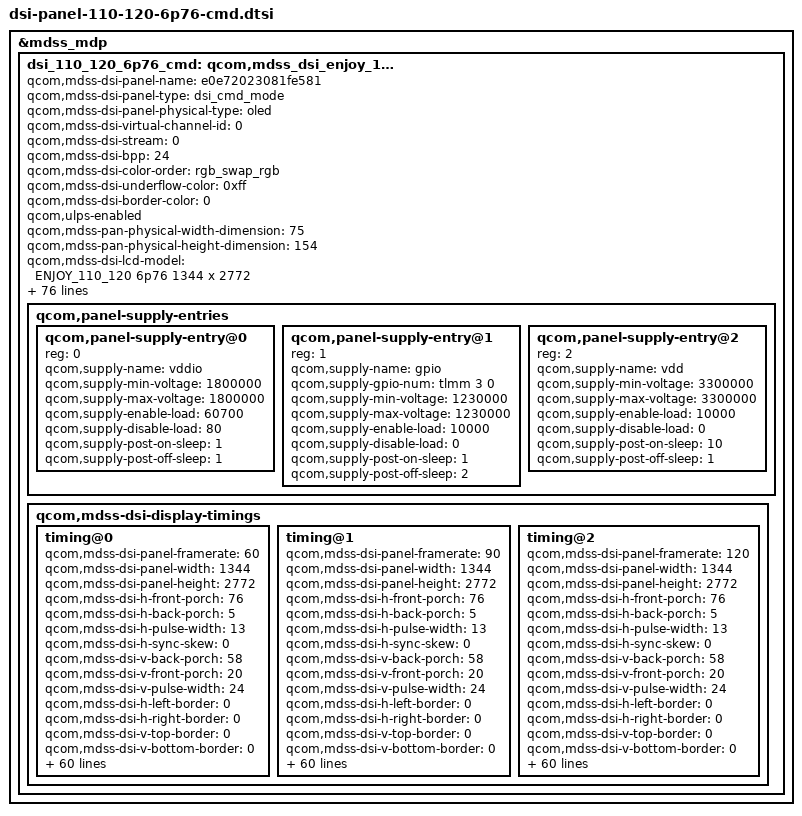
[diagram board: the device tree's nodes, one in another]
&mdss_mdp {
	dsi_110_120_6p76_cmd: qcom,mdss_dsi_enjoy_110_120_6p76_cmd {
		qcom,mdss-dsi-panel-name = "e0e72023081fe581";
		qcom,mdss-dsi-panel-type = "dsi_cmd_mode";
		qcom,mdss-dsi-panel-physical-type = "oled";
		qcom,mdss-dsi-virtual-channel-id = <0>;
		qcom,mdss-dsi-stream = <0>;
		qcom,mdss-dsi-bpp = <24>;
		qcom,mdss-dsi-color-order = "rgb_swap_rgb";
		qcom,mdss-dsi-underflow-color = <0xff>;
		qcom,mdss-dsi-border-color = <0>;
		qcom,ulps-enabled;
		qcom,mdss-pan-physical-width-dimension = <75>;
		qcom,mdss-pan-physical-height-dimension = <154>;
		qcom,mdss-dsi-lcd-model = "ENJOY_110_120 6p76 1344 x 2772";

		/* mipi dsi setting */
		qcom,dsi-ctrl-num = <0>;
		qcom,dsi-phy-num = <0>;
		qcom,dsi-sec-ctrl-num = <1>;
		qcom,dsi-sec-phy-num = <1>;
		qcom,mdss-dsi-traffic-mode = "non_burst_sync_event";
		qcom,mdss-dsi-lane-map = "lane_map_0123";
		qcom,mdss-dsi-bllp-eof-power-mode;
		qcom,mdss-dsi-bllp-power-mode;
		qcom,mdss-dsi-lane-0-state;
		qcom,mdss-dsi-lane-1-state;
		qcom,mdss-dsi-lane-2-state;
		qcom,mdss-dsi-lane-3-state;
		qcom,mdss-dsi-dma-trigger = "trigger_sw";
		qcom,mdss-dsi-mdp-trigger = "none";
		qcom,dsi-select-clocks = "mux_byte_clk0", "mux_pixel_clk0";
		qcom,dsi-select-sec-clocks = "mux_byte_clk1", "mux_pixel_clk1";

		/* TE setting */
		qcom,mdss-dsi-te-pin-select = <1>;
		qcom,mdss-dsi-wr-mem-start = <0x2c>;
		qcom,mdss-dsi-wr-mem-continue = <0x3c>;
		qcom,mdss-dsi-te-dcs-command = <1>;
		qcom,mdss-dsi-te-check-enable;
		qcom,mdss-dsi-te-using-te-pin;

		/* hdr setting */
		qcom,mdss-dsi-panel-hdr-enabled;
		qcom,mdss-dsi-panel-hdr-color-primaries = <14500 15500 32000
			17000 15500 30000 8000 3000>;
		qcom,mdss-dsi-panel-peak-brightness = <4200000>;
		qcom,mdss-dsi-panel-blackness-level = <3230>;

		/* hbm enable */
		qcom,mdss-dsi-panel-hbm-enabled;
		/* hbm delay threshold */
		qcom,mdss-dsi-hbm-left-delaythr = <0>;
		qcom,mdss-dsi-hbm-right-delaythr = <5000>;
		qcom,mdss-dsi-panel-read-batch-info-enabled;
		qcom,mdss-dsi-panel-batch-match-hbm-enabled;
		qcom,mdss-dsi-panel-batch-value = <0x04>;

		/* gpio setting */
		qcom,dsi-panel-gpio-address = <0x0F100000 0x1000>;
		qcom,dsi-panel-gpio-pins = <24 3>;
		qcom,dsi-panel-gpio-names = "reset-gpio", "vdd-gpio";

		/* esd check setting */
		qcom,mdss-dsi-panel-status-check-mode = "reg_read";
		qcom,mdss-dsi-panel-status-command = [
			06 01 00 01 00 00 01 0a
			06 01 00 01 00 00 01 03
			06 01 00 01 00 00 01 0d
			06 01 00 01 00 00 01 91
		];
		qcom,mdss-dsi-panel-status-command-state = "dsi_lp_mode";
		qcom,mdss-dsi-panel-status-value = <0x9c 0x01 0x00 0xab>;
		qcom,mdss-dsi-panel-status-read-length = <1 1 1 1>;
		qcom,esd-check-enabled;

		/* pcd detect*/
		qcom,mdss-dsi-panel-lcd-check-pcd-support;
		qcom,mdss-dsi-panel-lcd-pcd_value_compare_mode = <1>;
		qcom,mdss-dsi-panel-lcd-pcd_mask = <0xff>;
		qcom,mdss-dsi-panel-lcd-pcd_det_num = <1>;
		qcom,mdss-dsi-panel-lcd-check-pcd-expect_vals = <0xff>;

		/* check reg */
		qcom,mdss-dsi-panel-lcd-check-reg-enabled;
		qcom,mdss-dsi-panel-lcd-check-reg-expect_vals = <0x9c>;

		/* oem info */
		qcom,mdss-dsi-panel-oem-info-enabled;
		qcom,mdss-dsi-panel-oem-2d-barcode-enabled;
		qcom,mdss-dsi-panel-oem-sn-enabled;

		/* backlight setting */
		qcom,mdss-dsi-bl-pmic-control-type = "bl_ctrl_dcs";
		qcom,mdss-dsi-bl-min-level = <1>;
		qcom,mdss-dsi-bl-max-level = <4095>;
		qcom,mdss-brightness-max-level = <4095>;
		qcom,mdss-dsi-bl-inverted-dbv;
		qcom,mdss-dsi-bl-max-nit = <1000>;

		/* dfps setting */
		qcom,dsi-fps-list = <60 90 120>;

		/* power on/off timing setting */
		qcom,platform-reset-gpio = <&tlmm 24 0>;
		qcom,mdss-dsi-reset-sequence = <1 1>, <0 1>, <1 10>;
		qcom,mdss-dsi-reset-pre-off-sleep = <2>;
		qcom,mdss-dsi-panel-reset-in-lp11;
		qcom,panel-supply-entries {
			qcom,panel-supply-entry@0 {
					reg = <0>;
					qcom,supply-name = "vddio";
					qcom,supply-min-voltage = <1800000>;
					qcom,supply-max-voltage = <1800000>;
					qcom,supply-enable-load = <60700>;
					qcom,supply-disable-load = <80>;
					qcom,supply-post-on-sleep = <1>;
					qcom,supply-post-off-sleep = <1>;
			};
			qcom,panel-supply-entry@1 {
					reg = <1>;
					qcom,supply-name = "gpio";
					qcom,supply-gpio-num = <&tlmm 3 0>;
					qcom,supply-min-voltage = <1230000>;
					qcom,supply-max-voltage = <1230000>;
					qcom,supply-enable-load = <10000>;
					qcom,supply-disable-load = <0>;
					qcom,supply-post-on-sleep = <1>;
					qcom,supply-post-off-sleep = <2>;
			};
			qcom,panel-supply-entry@2 {
					reg = <2>;
					qcom,supply-name = "vdd";
					qcom,supply-min-voltage = <3300000>;
					qcom,supply-max-voltage = <3300000>;
					qcom,supply-enable-load = <10000>;
					qcom,supply-disable-load = <0>;
					qcom,supply-post-on-sleep = <10>;
					qcom,supply-post-off-sleep = <1>;
			};
		};
		/* display timing0 */
		qcom,mdss-dsi-display-timings {
			timing@0 {
				qcom,mdss-dsi-panel-framerate = <60>;
				qcom,mdss-dsi-panel-width = <1344>;
				qcom,mdss-dsi-panel-height = <2772>;
				qcom,mdss-dsi-h-front-porch = <76>;
				qcom,mdss-dsi-h-back-porch = <5>;
				qcom,mdss-dsi-h-pulse-width = <13>;
				qcom,mdss-dsi-h-sync-skew = <0>;
				qcom,mdss-dsi-v-back-porch = <58>;
				qcom,mdss-dsi-v-front-porch = <20>;
				qcom,mdss-dsi-v-pulse-width = <24>;
				qcom,mdss-dsi-h-left-border = <0>;
				qcom,mdss-dsi-h-right-border = <0>;
				qcom,mdss-dsi-v-top-border = <0>;
				qcom,mdss-dsi-v-bottom-border = <0>;
				qcom,mdss-dsi-panel-jitter = <0x4 0x1>;

				qcom,mdss-dsi-on-command = [
					39 01 00 00 00 00 06 F0 55 AA 52 08 05
					39 01 00 00 00 00 05 B7 85 00 00 81
					39 01 00 00 00 00 05 B8 05 00 00 81
					39 01 00 00 00 00 06 F0 55 AA 52 08 01
					15 01 00 00 00 00 02 6F 17
					15 01 00 00 00 00 02 D8 14
					39 01 00 00 00 00 06 F0 55 AA 52 08 07
					39 01 00 00 00 00 0E C0 1D 12 31 23 00 00 00 04 00 11 B3 00 00
					15 01 00 00 00 00 02 6F 00
					39 01 00 00 00 00 16 C9 21 00 2D 90 2D 90 00 00 3F D9 8E 80 3F D9 8E 80 80 08 1B F1 00
					15 01 00 00 00 00 02 6F 15
					39 01 00 00 00 00 10 C9 42 00 6E 42 6C DA 33 F0 2D 90 0F 94 94 00 00
					15 01 00 00 00 00 02 6F 24
					39 01 00 00 00 00 08 C9 00 00 00 00 00 00 00
					15 01 00 00 00 00 02 6F 00
					39 01 00 00 00 00 16 CA 27 00 2D 90 27 D9 00 00 00 00 00 00 3F DE 60 E8 80 00 00 00 00
					15 01 00 00 00 00 02 6F 15
					39 01 00 00 00 00 10 CA 42 6D 6E 42 D2 DA 33 D0 00 00 03 6C 9B 00 00
					15 01 00 00 00 00 02 6F 24
					39 01 00 00 00 00 08 CA 00 00 00 00 00 00 00
					15 01 00 00 00 00 02 6F 00
					39 01 00 00 00 00 16 CB 2D 00 2D 90 28 A4 00 00 3F DB B1 40 80 00 00 00 00 00 00 00 00
					15 01 00 00 00 00 02 6F 15
					39 01 00 00 00 00 10 CB 42 00 DB 52 66 47 33 E0 00 00 0C 94 66 00 00
					15 01 00 00 00 00 02 6F 24
					39 01 00 00 00 00 08 CB 00 00 00 00 00 00 00
					15 01 00 00 00 00 02 6F 00
					39 01 00 00 00 00 16 CC 2B 00 2D 90 2C B9 00 00 00 00 00 00 80 00 00 00 7F F8 0A 52 F0
					15 01 00 00 00 00 02 6F 15
					39 01 00 00 00 00 10 CC 42 67 DB 52 D2 47 33 CF D2 DC 00 6C 6B 00 00
					15 01 00 00 00 00 02 6F 24
					39 01 00 00 00 00 08 CC 00 00 00 00 00 00 00
                    			39 01 00 00 00 00 06 F0 55 AA 52 08 02
                   			39 01 00 00 00 00 05 88 02 9F 07 17
					39 01 00 00 00 00 06 F0 55 AA 52 08 01
					39 01 00 00 00 00 04 D2 00 40 00
					39 01 00 00 00 00 06 F0 55 AA 52 08 07
					15 01 00 00 00 00 02 C1 00
					15 01 00 00 00 00 02 C2 06
					15 01 00 00 00 00 02 C3 0C
					15 01 00 00 00 00 02 C4 0A
					15 01 00 00 00 00 02 C5 01
					15 01 00 00 00 00 02 C6 0D
					15 01 00 00 00 00 02 C7 07
					15 01 00 00 00 00 02 C8 0B
					39 01 00 00 00 00 06 F0 55 AA 52 08 00
					15 01 00 00 00 00 02 6F 02
					15 01 00 00 00 00 02 B5 46
					39 01 00 00 00 00 06 F0 55 AA 52 00 00
					39 01 00 00 00 00 05 FF AA 55 A5 00
					05 01 00 00 00 00 01 35
					39 01 00 00 00 00 05 3B 00 10 00 10
					39 01 00 00 00 00 02 53 20
					39 01 00 00 00 00 05 2A 00 00 05 3F
					39 01 00 00 00 00 05 2B 00 00 0A D3
					39 01 00 00 00 00 02 82 A6
					39 01 00 00 00 00 13 91 89 28 00 2C C2 00 02 50 04 BA 00 09 02 3C 01 DC 10 F0
					39 01 00 00 00 00 02 90 01
					39 01 00 00 00 00 02 03 01
					39 01 00 00 00 00 01 2C
					39 01 00 00 00 00 02 2F 01
					05 01 00 00 78 00 01 11
					05 01 00 00 00 00 01 29
				];

				qcom,mdss-dsi-off-command = [
					05 01 00 00 00 00 01 28
					05 01 00 00 64 00 01 10
				];

				qcom,mdss-dsi-fp-hbm-enable-commands = [
					39 01 00 00 00 00 03 51 0F FF
				];

				qcom,mdss-dsi-batchinfo-read-commands = [
					39 01 00 00 00 00 06 F0 55 AA 52 08 01
					06 01 00 01 00 00 01 DB
				];

				qcom,mdss-dsi-lhbm-enable-commands = [
					15 01 00 00 00 00 02 2F 04
					05 01 00 00 00 00 01 85
				];

				qcom,mdss-dsi-lhbm-disable-commands = [
					15 01 00 00 00 00 02 2F 01
					05 01 00 00 00 00 01 86
				];

				qcom,mdss-dsi-timing-switch-command = [
					15 01 00 00 0C 00 02 2F 01
				];

				qcom,mdss-dsi-lp1-command = [
					39 01 00 00 00 00 06 F0 55 AA 52 08 00
					15 00 00 00 00 00 02 6F 02
					15 00 00 00 00 00 02 B5 16
					15 00 00 00 00 00 02 2F 01
					05 00 00 00 00 00 01 39
					05 01 00 00 00 00 01 2C
				];

				qcom,mdss-dsi-nolp-command = [
					39 01 00 00 00 00 06 F0 55 AA 52 08 00
					15 00 00 00 00 00 02 6F 02
					15 00 00 00 00 00 02 B5 46
					05 00 00 00 00 00 01 38
					05 01 00 00 00 00 01 2C
				];

				qcom,mdss-dsi-alpm-low-light-commands = [
					39 01 00 00 00 00 05 51 01 77 00 03
				];

				qcom,mdss-dsi-alpm-middle-light-commands = [
					39 01 00 00 00 00 05 51 04 08 0A F0
				];

				qcom,mdss-dsi-alpm-high-light-commands = [
					39 01 00 00 00 00 05 51 05 73 0F FE
				];

				qcom,mdss-dsi-panel-lcd-check-reg-commands = [
					06 01 00 01 00 00 01 0a
				];

				qcom,mdss-dsi-oeminfo-read-commands = [
					39 01 00 00 00 00 06 F0 55 AA 52 08 01
					06 01 00 01 00 00 08 D6 00 00 00 00 00 00 00
					06 01 00 01 00 00 06 BF 00 00 00 00 00
					06 01 00 01 00 00 08 D7 00 00 00 00 00 00 00
				];

				qcom,mdss-dsi-lcd-pcd-check-open-commands = [
					39 01 00 00 0a 00 06 F0 55 AA 52 08 01
					39 01 00 00 0a 00 05 D0 00 31 00 00
				];

				qcom,mdss-dsi-lcd-pcd-check-reg-commands = [
					39 01 00 00 0a 00 06 F0 55 AA 52 08 01
					15 01 00 00 0a 00 02 6F 02
					06 01 00 00 0A 00 01 D0
				];

				qcom,mdss-dsi-lcd-pcd-check-close-commands = [
					39 01 00 00 78 00 06 F0 55 AA 52 08 01
					39 01 00 00 0A 00 03 D0 00 00
				];

				qcom,mdss-dsi-on-command-state = "dsi_lp_mode";
				qcom,mdss-dsi-off-command-state = "dsi_hs_mode";
				qcom,mdss-dsi-panel-lcd-check-reg-commands-state =
					"dsi_lp_mode";
				qcom,mdss-dsi-oeminfo-read-commands-state =
					"dsi_lp_mode";
				qcom,mdss-dsi-lcd-pcd-check-open-commands-state =
					"dsi_lp_mode";
				qcom,mdss-dsi-lcd-pcd-check-reg-commands-state =
					"dsi_lp_mode";
				qcom,mdss-dsi-lcd-pcd-check-close-commands-state =
					"dsi_lp_mode";

				qcom,mdss-dsi-h-sync-pulse = <0>;
				qcom,compression-mode = "dsc";
				qcom,mdss-dsc-version = <0x12>;
				qcom,mdss-dsc-slice-height = <44>;
				qcom,mdss-dsc-slice-width = <672>;
				qcom,mdss-dsc-slice-per-pkt = <2>;
				qcom,mdss-dsc-bit-per-component = <10>;
				qcom,mdss-dsc-bit-per-pixel = <8>;
				qcom,mdss-dsc-block-prediction-enable;
				qcom,mdss-dsi-panel-phy-timings = [00 14 05 05 13 1f 05
						05 05 06 02 04 12 0a];
				qcom,display-topology = <2 2 1>;
				qcom,default-topology-index = <0>;
			};
			timing@1 {
				qcom,mdss-dsi-panel-framerate = <90>;
				qcom,mdss-dsi-panel-width = <1344>;
				qcom,mdss-dsi-panel-height = <2772>;
				qcom,mdss-dsi-h-front-porch = <76>;
				qcom,mdss-dsi-h-back-porch = <5>;
				qcom,mdss-dsi-h-pulse-width = <13>;
				qcom,mdss-dsi-h-sync-skew = <0>;
				qcom,mdss-dsi-v-back-porch = <58>;
				qcom,mdss-dsi-v-front-porch = <20>;
				qcom,mdss-dsi-v-pulse-width = <24>;
				qcom,mdss-dsi-h-left-border = <0>;
				qcom,mdss-dsi-h-right-border = <0>;
				qcom,mdss-dsi-v-top-border = <0>;
				qcom,mdss-dsi-v-bottom-border = <0>;
				qcom,mdss-dsi-panel-jitter = <0x4 0x1>;

				qcom,mdss-dsi-on-command = [
					39 01 00 00 00 00 06 F0 55 AA 52 08 05
					39 01 00 00 00 00 05 B7 85 00 00 81
					39 01 00 00 00 00 05 B8 05 00 00 81
					39 01 00 00 00 00 06 F0 55 AA 52 08 01
					15 01 00 00 00 00 02 6F 17
					15 01 00 00 00 00 02 D8 14
					39 01 00 00 00 00 06 F0 55 AA 52 08 07
					39 01 00 00 00 00 0E C0 1D 12 31 23 00 00 00 04 00 11 B3 00 00
					15 01 00 00 00 00 02 6F 00
					39 01 00 00 00 00 16 C9 21 00 2D 90 2D 90 00 00 3F D9 8E 80 3F D9 8E 80 80 08 1B F1 00
					15 01 00 00 00 00 02 6F 15
					39 01 00 00 00 00 10 C9 42 00 6E 42 6C DA 33 F0 2D 90 0F 94 94 00 00
					15 01 00 00 00 00 02 6F 24
					39 01 00 00 00 00 08 C9 00 00 00 00 00 00 00
					15 01 00 00 00 00 02 6F 00
					39 01 00 00 00 00 16 CA 27 00 2D 90 27 D9 00 00 00 00 00 00 3F DE 60 E8 80 00 00 00 00
					15 01 00 00 00 00 02 6F 15
					39 01 00 00 00 00 10 CA 42 6D 6E 42 D2 DA 33 D0 00 00 03 6C 9B 00 00
					15 01 00 00 00 00 02 6F 24
					39 01 00 00 00 00 08 CA 00 00 00 00 00 00 00
					15 01 00 00 00 00 02 6F 00
					39 01 00 00 00 00 16 CB 2D 00 2D 90 28 A4 00 00 3F DB B1 40 80 00 00 00 00 00 00 00 00
					15 01 00 00 00 00 02 6F 15
					39 01 00 00 00 00 10 CB 42 00 DB 52 66 47 33 E0 00 00 0C 94 66 00 00
					15 01 00 00 00 00 02 6F 24
					39 01 00 00 00 00 08 CB 00 00 00 00 00 00 00
					15 01 00 00 00 00 02 6F 00
					39 01 00 00 00 00 16 CC 2B 00 2D 90 2C B9 00 00 00 00 00 00 80 00 00 00 7F F8 0A 52 F0
					15 01 00 00 00 00 02 6F 15
					39 01 00 00 00 00 10 CC 42 67 DB 52 D2 47 33 CF D2 DC 00 6C 6B 00 00
					15 01 00 00 00 00 02 6F 24
					39 01 00 00 00 00 08 CC 00 00 00 00 00 00 00
					39 01 00 00 00 00 06 F0 55 AA 52 08 02
					39 01 00 00 00 00 05 88 02 9F 07 17
					39 01 00 00 00 00 06 F0 55 AA 52 08 01
					39 01 00 00 00 00 04 D2 00 40 00
					39 01 00 00 00 00 06 F0 55 AA 52 08 07
					15 01 00 00 00 00 02 C1 00
					15 01 00 00 00 00 02 C2 06
					15 01 00 00 00 00 02 C3 0C
					15 01 00 00 00 00 02 C4 0A
					15 01 00 00 00 00 02 C5 01
					15 01 00 00 00 00 02 C6 0D
					15 01 00 00 00 00 02 C7 07
					15 01 00 00 00 00 02 C8 0B
                    			39 01 00 00 00 00 06 F0 55 AA 52 08 00
					15 01 00 00 00 00 02 6F 02
					15 01 00 00 00 00 02 B5 46
					39 01 00 00 00 00 06 F0 55 AA 52 00 00
					39 01 00 00 00 00 05 FF AA 55 A5 00
					05 01 00 00 00 00 01 35
					39 01 00 00 00 00 05 3B 00 10 00 10
					39 01 00 00 00 00 02 53 20
					39 01 00 00 00 00 05 2A 00 00 05 3F
					39 01 00 00 00 00 05 2B 00 00 0A D3
					39 01 00 00 00 00 02 82 A6
					39 01 00 00 00 00 13 91 89 28 00 2C C2 00 02 50 04 BA 00 09 02 3C 01 DC 10 F0
					39 01 00 00 00 00 02 90 01
					39 01 00 00 00 00 02 03 01
					39 01 00 00 00 00 01 2C
					05 01 00 00 78 00 01 11
					05 01 00 00 00 00 01 29
					39 01 00 00 00 00 02 2F 02
				];

				qcom,mdss-dsi-off-command = [
					05 01 00 00 00 00 01 28
					05 01 00 00 64 00 01 10
				];

				qcom,mdss-dsi-fp-hbm-enable-commands = [
					39 01 00 00 00 00 03 51 0F FF
				];

				qcom,mdss-dsi-batchinfo-read-commands = [
					39 01 00 00 00 00 06 F0 55 AA 52 08 01
					06 01 00 01 00 00 01 DB
				];

				qcom,mdss-dsi-lhbm-enable-commands = [
					15 01 00 00 00 00 02 2F 04
					05 01 00 00 00 00 01 85
				];

				qcom,mdss-dsi-lhbm-disable-commands = [
					15 01 00 00 00 00 02 2F 02
					05 01 00 00 00 00 01 86
				];

				qcom,mdss-dsi-timing-switch-command = [
					15 01 00 00 09 00 02 2F 02
				];

				qcom,mdss-dsi-lp1-command = [
					39 01 00 00 00 00 06 F0 55 AA 52 08 00
					15 00 00 00 00 00 02 6F 02
					15 00 00 00 00 00 02 B5 16
					15 00 00 00 00 00 02 2F 01
                    			05 00 00 00 00 00 01 39
					05 01 00 00 00 00 01 2C
				];

				qcom,mdss-dsi-nolp-command = [
					39 01 00 00 00 00 06 F0 55 AA 52 08 00
					15 00 00 00 00 00 02 6F 02
					15 00 00 00 00 00 02 B5 46
					05 00 00 00 00 00 01 38
					39 00 00 00 00 00 02 2F 02
					05 01 00 00 00 00 01 2C
				];

				qcom,mdss-dsi-alpm-low-light-commands = [
					39 01 00 00 00 00 05 51 01 77 00 03
				];

				qcom,mdss-dsi-alpm-middle-light-commands = [
					39 01 00 00 00 00 05 51 04 08 0A F0
				];

				qcom,mdss-dsi-alpm-high-light-commands = [
					39 01 00 00 00 00 05 51 05 73 0F FE
				];

				qcom,mdss-dsi-panel-lcd-check-reg-commands = [
					06 01 00 01 00 00 01 0a
				];

				qcom,mdss-dsi-oeminfo-read-commands = [
					39 01 00 00 00 00 06 F0 55 AA 52 08 01
					06 01 00 01 00 00 08 D6 00 00 00 00 00 00 00
					06 01 00 01 00 00 06 BF 00 00 00 00 00
					06 01 00 01 00 00 08 D7 00 00 00 00 00 00 00
				];

				qcom,mdss-dsi-lcd-pcd-check-open-commands = [
					39 01 00 00 0a 00 06 F0 55 AA 52 08 01
					39 01 00 00 0a 00 05 D0 00 31 00 00
				];

				qcom,mdss-dsi-lcd-pcd-check-reg-commands = [
					39 01 00 00 0a 00 06 F0 55 AA 52 08 01
					15 01 00 00 0a 00 02 6F 02
					06 01 00 00 0A 00 01 D0
				];

				qcom,mdss-dsi-lcd-pcd-check-close-commands = [
					39 01 00 00 78 00 06 F0 55 AA 52 08 01
					39 01 00 00 0A 00 03 D0 00 00
				];

				qcom,mdss-dsi-on-command-state = "dsi_lp_mode";
				qcom,mdss-dsi-off-command-state = "dsi_hs_mode";
				qcom,mdss-dsi-panel-lcd-check-reg-commands-state =
					"dsi_lp_mode";
				qcom,mdss-dsi-oeminfo-read-commands-state =
					"dsi_lp_mode";
				qcom,mdss-dsi-lcd-pcd-check-open-commands-state =
					"dsi_lp_mode";
				qcom,mdss-dsi-lcd-pcd-check-reg-commands-state =
					"dsi_lp_mode";
				qcom,mdss-dsi-lcd-pcd-check-close-commands-state =
					"dsi_lp_mode";

				qcom,mdss-dsi-h-sync-pulse = <0>;
				qcom,compression-mode = "dsc";
				qcom,mdss-dsc-version = <0x12>;
				qcom,mdss-dsc-slice-height = <44>;
				qcom,mdss-dsc-slice-width = <672>;
				qcom,mdss-dsc-slice-per-pkt = <2>;
				qcom,mdss-dsc-bit-per-component = <10>;
				qcom,mdss-dsc-bit-per-pixel = <8>;
				qcom,mdss-dsc-block-prediction-enable;
				qcom,mdss-dsi-panel-phy-timings = [00 1d 07 07 17 22 07
					07 07 08 02 04 19 0c];
				qcom,display-topology = <2 2 1>;
				qcom,default-topology-index = <0>;
			};
			timing@2 {
				qcom,mdss-dsi-panel-framerate = <120>;
				qcom,mdss-dsi-panel-width = <1344>;
				qcom,mdss-dsi-panel-height = <2772>;
				qcom,mdss-dsi-h-front-porch = <76>;
				qcom,mdss-dsi-h-back-porch = <5>;
				qcom,mdss-dsi-h-pulse-width = <13>;
				qcom,mdss-dsi-h-sync-skew = <0>;
				qcom,mdss-dsi-v-back-porch = <58>;
				qcom,mdss-dsi-v-front-porch = <20>;
				qcom,mdss-dsi-v-pulse-width = <24>;
				qcom,mdss-dsi-h-left-border = <0>;
				qcom,mdss-dsi-h-right-border = <0>;
				qcom,mdss-dsi-v-top-border = <0>;
				qcom,mdss-dsi-v-bottom-border = <0>;
				qcom,mdss-dsi-panel-jitter = <0x4 0x1>;

				qcom,mdss-dsi-on-command = [
					39 01 00 00 00 00 06 F0 55 AA 52 08 05
					39 01 00 00 00 00 05 B7 85 00 00 81
					39 01 00 00 00 00 05 B8 05 00 00 81
					39 01 00 00 00 00 06 F0 55 AA 52 08 01
					15 01 00 00 00 00 02 6F 17
					15 01 00 00 00 00 02 D8 14
					39 01 00 00 00 00 06 F0 55 AA 52 08 07
					39 01 00 00 00 00 0E C0 1D 12 31 23 00 00 00 04 00 11 B3 00 00
					15 01 00 00 00 00 02 6F 00
					39 01 00 00 00 00 16 C9 21 00 2D 90 2D 90 00 00 3F D9 8E 80 3F D9 8E 80 80 08 1B F1 00
					15 01 00 00 00 00 02 6F 15
					39 01 00 00 00 00 10 C9 42 00 6E 42 6C DA 33 F0 2D 90 0F 94 94 00 00
					15 01 00 00 00 00 02 6F 24
					39 01 00 00 00 00 08 C9 00 00 00 00 00 00 00
					15 01 00 00 00 00 02 6F 00
					39 01 00 00 00 00 16 CA 27 00 2D 90 27 D9 00 00 00 00 00 00 3F DE 60 E8 80 00 00 00 00
					15 01 00 00 00 00 02 6F 15
					39 01 00 00 00 00 10 CA 42 6D 6E 42 D2 DA 33 D0 00 00 03 6C 9B 00 00
					15 01 00 00 00 00 02 6F 24
					39 01 00 00 00 00 08 CA 00 00 00 00 00 00 00
					15 01 00 00 00 00 02 6F 00
					39 01 00 00 00 00 16 CB 2D 00 2D 90 28 A4 00 00 3F DB B1 40 80 00 00 00 00 00 00 00 00
					15 01 00 00 00 00 02 6F 15
					39 01 00 00 00 00 10 CB 42 00 DB 52 66 47 33 E0 00 00 0C 94 66 00 00
					15 01 00 00 00 00 02 6F 24
					39 01 00 00 00 00 08 CB 00 00 00 00 00 00 00
					15 01 00 00 00 00 02 6F 00
					39 01 00 00 00 00 16 CC 2B 00 2D 90 2C B9 00 00 00 00 00 00 80 00 00 00 7F F8 0A 52 F0
					15 01 00 00 00 00 02 6F 15
					39 01 00 00 00 00 10 CC 42 67 DB 52 D2 47 33 CF D2 DC 00 6C 6B 00 00
					15 01 00 00 00 00 02 6F 24
					39 01 00 00 00 00 08 CC 00 00 00 00 00 00 00
					39 01 00 00 00 00 06 F0 55 AA 52 08 02
					39 01 00 00 00 00 05 88 02 9F 07 17
					39 01 00 00 00 00 06 F0 55 AA 52 08 01
					39 01 00 00 00 00 04 D2 00 40 00
					39 01 00 00 00 00 06 F0 55 AA 52 08 07
					15 01 00 00 00 00 02 C1 00
					15 01 00 00 00 00 02 C2 06
					15 01 00 00 00 00 02 C3 0C
					15 01 00 00 00 00 02 C4 0A
					15 01 00 00 00 00 02 C5 01
					15 01 00 00 00 00 02 C6 0D
					15 01 00 00 00 00 02 C7 07
					15 01 00 00 00 00 02 C8 0B
					39 01 00 00 00 00 06 F0 55 AA 52 08 00
					15 01 00 00 00 00 02 6F 02
					15 01 00 00 00 00 02 B5 46
					39 01 00 00 00 00 06 F0 55 AA 52 00 00
					39 01 00 00 00 00 05 FF AA 55 A5 00
					05 01 00 00 00 00 01 35
					39 01 00 00 00 00 05 3B 00 10 00 10
					39 01 00 00 00 00 02 53 20
					39 01 00 00 00 00 05 2A 00 00 05 3F
					39 01 00 00 00 00 05 2B 00 00 0A D3
					39 01 00 00 00 00 02 82 A6
					39 01 00 00 00 00 13 91 89 28 00 2C C2 00 02 50 04 BA 00 09 02 3C 01 DC 10 F0
					39 01 00 00 00 00 02 90 01
					39 01 00 00 00 00 02 03 01
					39 01 00 00 00 00 01 2C
					05 01 00 00 78 00 01 11
					05 01 00 00 00 00 01 29
					39 01 00 00 00 00 02 2F 03
				];

				qcom,mdss-dsi-off-command = [
					05 01 00 00 00 00 01 28
					05 01 00 00 64 00 01 10
				];

				qcom,mdss-dsi-fp-hbm-enable-commands = [
					39 01 00 00 00 00 03 51 0F FF
				];

				qcom,mdss-dsi-batchinfo-read-commands = [
					39 01 00 00 00 00 06 F0 55 AA 52 08 01
					06 01 00 01 00 00 01 DB
				];

				qcom,mdss-dsi-lhbm-enable-commands = [
					15 01 00 00 00 00 02 2F 04
					05 01 00 00 00 00 01 85
				];

				qcom,mdss-dsi-lhbm-disable-commands = [
					15 01 00 00 00 00 02 2F 03
					05 01 00 00 00 00 01 86
				];

				qcom,mdss-dsi-timing-switch-command = [
					15 01 00 00 00 00 02 2F 03
				];

				qcom,mdss-dsi-lp1-command = [
					39 01 00 00 00 00 06 F0 55 AA 52 08 00
					15 00 00 00 00 00 02 6F 02
					15 00 00 00 00 00 02 B5 16
					15 00 00 00 00 00 02 2F 01
					05 00 00 00 00 00 01 39
                    			05 01 00 00 00 00 01 2C
				];

				qcom,mdss-dsi-nolp-command = [
					39 01 00 00 00 00 06 F0 55 AA 52 08 00
					15 00 00 00 00 00 02 6F 02
					15 00 00 00 00 00 02 B5 46
					05 00 00 00 00 00 01 38
					15 00 00 00 00 00 02 2F 03
                    			05 01 00 00 00 00 01 2C
				];

				qcom,mdss-dsi-alpm-low-light-commands = [
					39 01 00 00 00 00 05 51 01 77 00 03
				];

				qcom,mdss-dsi-alpm-middle-light-commands = [
					39 01 00 00 00 00 05 51 04 08 0A F0
				];

				qcom,mdss-dsi-alpm-high-light-commands = [
					39 01 00 00 00 00 05 51 05 73 0F FE
				];

				qcom,mdss-dsi-panel-lcd-check-reg-commands = [
					06 01 00 01 00 00 01 0a
				];

				qcom,mdss-dsi-oeminfo-read-commands = [
					39 01 00 00 00 00 06 F0 55 AA 52 08 01
					06 01 00 01 00 00 08 D6 00 00 00 00 00 00 00
					06 01 00 01 00 00 06 BF 00 00 00 00 00
					06 01 00 01 00 00 08 D7 00 00 00 00 00 00 00
				];

				qcom,mdss-dsi-lcd-pcd-check-open-commands = [
					39 01 00 00 0a 00 06 F0 55 AA 52 08 01
					39 01 00 00 0a 00 05 D0 00 31 00 00
				];

				qcom,mdss-dsi-lcd-pcd-check-reg-commands = [
					39 01 00 00 0a 00 06 F0 55 AA 52 08 01
					15 01 00 00 0a 00 02 6F 02
					06 01 00 00 0A 00 01 D0
				];

				qcom,mdss-dsi-lcd-pcd-check-close-commands = [
					39 01 00 00 78 00 06 F0 55 AA 52 08 01
					39 01 00 00 0A 00 03 D0 00 00
				];

				qcom,mdss-dsi-on-command-state = "dsi_lp_mode";
				qcom,mdss-dsi-off-command-state = "dsi_hs_mode";
				qcom,mdss-dsi-panel-lcd-check-reg-commands-state =
					"dsi_lp_mode";
				qcom,mdss-dsi-oeminfo-read-commands-state =
					"dsi_lp_mode";
				qcom,mdss-dsi-lcd-pcd-check-open-commands-state =
					"dsi_lp_mode";
				qcom,mdss-dsi-lcd-pcd-check-reg-commands-state =
					"dsi_lp_mode";
				qcom,mdss-dsi-lcd-pcd-check-close-commands-state =
					"dsi_lp_mode";

				qcom,mdss-dsi-h-sync-pulse = <0>;
				qcom,compression-mode = "dsc";
				qcom,mdss-dsc-version = <0x12>;
				qcom,mdss-dsc-slice-height = <44>;
				qcom,mdss-dsc-slice-width = <672>;
				qcom,mdss-dsc-slice-per-pkt = <2>;
				qcom,mdss-dsc-bit-per-component = <10>;
				qcom,mdss-dsc-bit-per-pixel = <8>;
				qcom,mdss-dsc-block-prediction-enable;
				qcom,mdss-dsi-panel-phy-timings = [00 25 0a 0a 1b 18 0a
					0a 0a 0a 02 04 1f 0f];
				qcom,display-topology = <2 2 1>;
				qcom,default-topology-index = <0>;
			};
		};
	};
};

